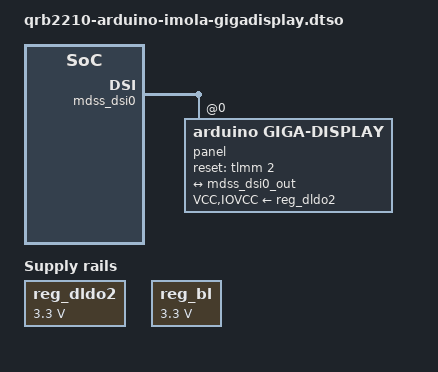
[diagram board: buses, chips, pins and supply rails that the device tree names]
// SPDX-License-Identifier: (GPL-2.0+ OR BSD-3-Clause)
/*
 * Copyright (c) 2025, Arduino SA
 */

/dts-v1/;
/plugin/;

#include <dt-bindings/gpio/gpio.h>

/ {
	reg_dldo2: reg-dldo2 {
		compatible = "regulator-fixed";
		regulator-name = "mipi_panel_reg";
		regulator-min-microvolt = <3300000>;
		regulator-max-microvolt = <3300000>;
		regulator-always-on;
	};

	reg_bl: reg-bl {
		compatible = "regulator-fixed";
		regulator-name = "mipi_panel_backlight";
		regulator-min-microvolt = <3300000>;
		regulator-max-microvolt = <3300000>;
		regulator-always-on;
	};
};

&mdss_dsi0 {
	vdda-supply = <&pm4125_l5>;
	status = "okay";

	#address-cells = <1>;
	#size-cells = <0>;

	panel@0 {
		compatible = "arduino,giga-display","sitronix,st7701";
		reg = <0x0>;
		VCC-supply = <&reg_dldo2>;
		IOVCC-supply = <&reg_dldo2>;
		reset-gpios = <&tlmm 2 GPIO_ACTIVE_HIGH>;
		dsi-lanes = <2>;
		video-mode = <2>;	/* 0: burst mode
					 * 1: non-burst mode with sync event
					 * 2: non-burst mode with sync pulse
					 */
		status = "okay";

		port {
			panel0_in: endpoint {
				remote-endpoint = <&mdss_dsi0_out>;
			};
		};
	};
};

&mdss_dsi0_out {
	remote-endpoint = <&panel0_in>;
	data-lanes = <0 1>;
};

&anx_dsi0_in {
	remote-endpoint = <>;
};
